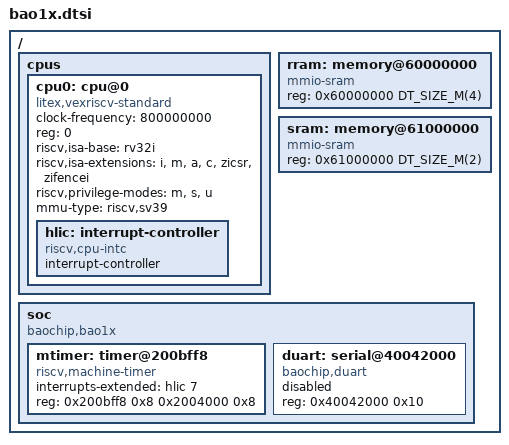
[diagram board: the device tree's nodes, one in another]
/*
 * Copyright (c) 2026 Baochip contributors
 * SPDX-License-Identifier: Apache-2.0
 *
 * Baochip bao1x SoC (LiteX / VexRiscv AXI4, RV32IMAC Sv39).
 */

#include <mem.h>

/ {
	#address-cells = <1>;
	#size-cells = <1>;

	cpus {
		#address-cells = <1>;
		#size-cells = <0>;

		cpu0: cpu@0 {
			clock-frequency = <800000000>;
			compatible = "litex,vexriscv-standard", "spinalhdl,vexriscv", "riscv";
			device_type = "cpu";
			reg = <0>;
			riscv,isa-base = "rv32i";
			riscv,isa-extensions = "i", "m", "a", "c", "zicsr", "zifencei";
			riscv,privilege-modes = "m", "s", "u";
			mmu-type = "riscv,sv39";
			status = "okay";

			hlic: interrupt-controller {
				compatible = "riscv,cpu-intc";
				#address-cells = <0>;
				#interrupt-cells = <1>;
				interrupt-controller;
			};
		};
	};

	rram: memory@60000000 {
		compatible = "mmio-sram";
		reg = <0x60000000 DT_SIZE_M(4)>;
	};

	sram: memory@61000000 {
		compatible = "mmio-sram";
		reg = <0x61000000 DT_SIZE_M(2)>;
	};

	soc {
		#address-cells = <1>;
		#size-cells = <1>;
		compatible = "baochip,bao1x", "simple-bus";
		ranges;

		mtimer: timer@200bff8 {
			compatible = "riscv,machine-timer";
			interrupts-extended = <&hlic 7>;
			reg = <0x200bff8 0x8 0x2004000 0x8>;
			reg-names = "mtime", "mtimecmp";
		};

		duart: serial@40042000 {
			compatible = "baochip,duart";
			reg = <0x40042000 0x10>;
			status = "disabled";
		};
	};
};
